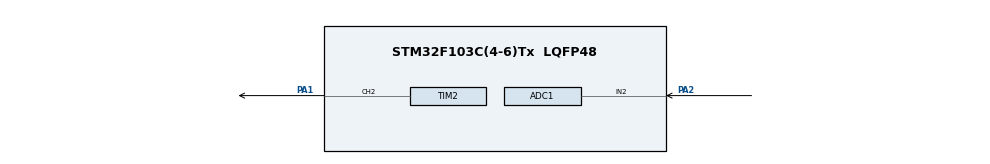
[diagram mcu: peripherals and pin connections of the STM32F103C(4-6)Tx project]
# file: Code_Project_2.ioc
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ADC1.Channel-1\#ChannelRegularConversion=ADC_CHANNEL_2
ADC1.ExternalTrigConv=ADC_SOFTWARE_START
ADC1.NbrOfConversion=1
ADC1.NbrOfConversionFlag=1
ADC1.Rank-1\#ChannelRegularConversion=1
ADC1.SamplingTime-1\#ChannelRegularConversion=ADC_SAMPLETIME_1CYCLE_5
ADC1.master=1
Mcu.Family=STM32F1
Mcu.Name=STM32F103C(4-6)Tx
Mcu.Package=LQFP48
NVIC.PriorityGroup=NVIC_PRIORITYGROUP_4
PA1.Signal=S_TIM2_CH2
PA13.Mode=Serial_Wire
PA13.Signal=SYS_JTMS-SWDIO
PA14.Mode=Serial_Wire
PA14.Signal=SYS_JTCK-SWCLK
PA2.Signal=ADCx_IN2
ProjectManager.HeapSize=0x200
ProjectManager.StackSize=0x400
ProjectManager.TargetToolchain=STM32CubeIDE
RCC.APB1Freq_Value=8000000
RCC.APB2Freq_Value=8000000
SH.ADCx_IN2.0=ADC1_IN2,IN2
SH.S_TIM2_CH2.0=TIM2_CH2,PWM Generation2 CH2
TIM2.Channel-PWM\ Generation2\ CH2=TIM_CHANNEL_2
TIM2.Period=99
TIM2.Prescaler=79
TIM2.Pulse-PWM\ Generation2\ CH2=10
VP_TIM2_VS_ClockSourceINT.Mode=Internal
board=custom

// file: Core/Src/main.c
/* USER CODE BEGIN Header */
/**
  ******************************************************************************
  * @file           : main.c
  * @brief          : Main program body
  ******************************************************************************
  * @attention
  *
  * <h2><center>&copy; Copyright (c) 2021 STMicroelectronics.
  * All rights reserved.</center></h2>
  *
  * This software component is licensed by ST under BSD 3-Clause license,
  * the "License"; You may not use this file except in compliance with the
  * License. You may obtain a copy of the License at:
  *                        opensource.org/licenses/BSD-3-Clause
  *
  ******************************************************************************
  */
/* USER CODE END Header */
#include "main.h"

ADC_HandleTypeDef hadc1;

TIM_HandleTypeDef htim2;

/* USER CODE BEGIN PV */

//variable for PID
float 	 alpha = 0, beta = 0, gamma = 0;
uint8_t  duty = 0, pre_duty = 0;

/* USER CODE END PV */

void SystemClock_Config(void);
static void MX_GPIO_Init(void);
static void MX_ADC1_Init(void);
static void MX_TIM2_Init(void);
/* USER CODE BEGIN PFP */
void TIM2_PWM_Set_Duty(uint8_t duty);
void TIM2_PWM_Set_Frequency(uint32_t frequency);
/* USER CODE END PFP */

int main(void)
{

  /* MCU Configuration--------------------------------------------------------*/

  /* Reset of all peripherals, Initializes the Flash interface and the Systick. */
  HAL_Init();

  /* USER CODE BEGIN Init */
  Lcd_Init();
  /* USER CODE END Init */

  /* Configure the system clock */
  SystemClock_Config();

  /* Initialize all configured peripherals */
  MX_GPIO_Init();
  MX_ADC1_Init();
  MX_TIM2_Init();
  /* USER CODE BEGIN 2 */
  Lcd_display(10, 1000);

  TIM2_PWM_Set_Duty(10);
  TIM2_PWM_Set_Frequency(2000);
  if( HAL_TIM_PWM_Start(&htim2, TIM_CHANNEL_2) != HAL_OK)
  {
	  Error_Handler();
  }
  /* USER CODE END 2 */

  /* Infinite loop */
  /* USER CODE BEGIN WHILE */
  uint8_t temperature;
  while (1)
  {

//	  while(duty <= 100)
//	  {
//		  TIM2_PWM_Set_Duty(duty);
//		  HAL_Delay(50);
//		  duty += 5;
//	  }
//	  duty = 0;

	HAL_ADC_Start(&hadc1);
	temperature = ((float)HAL_ADC_GetValue(&hadc1) / 4096) * 3.3 * 100;
	Lcd_display(temperature, 500);
	HAL_Delay(1000);
    /* USER CODE END WHILE */

  }
}

void SystemClock_Config(void)
{
  RCC_OscInitTypeDef RCC_OscInitStruct = {0};
  RCC_ClkInitTypeDef RCC_ClkInitStruct = {0};
  RCC_PeriphCLKInitTypeDef PeriphClkInit = {0};

  /** Initializes the RCC Oscillators according to the specified parameters
  * in the RCC_OscInitTypeDef structure.
  */
  RCC_OscInitStruct.OscillatorType = RCC_OSCILLATORTYPE_HSI;
  RCC_OscInitStruct.HSIState = RCC_HSI_ON;
  RCC_OscInitStruct.HSICalibrationValue = RCC_HSICALIBRATION_DEFAULT;
  RCC_OscInitStruct.PLL.PLLState = RCC_PLL_NONE;
  if (HAL_RCC_OscConfig(&RCC_OscInitStruct) != HAL_OK)
  {
    Error_Handler();
  }
  /** Initializes the CPU, AHB and APB buses clocks
  */
  RCC_ClkInitStruct.ClockType = RCC_CLOCKTYPE_HCLK|RCC_CLOCKTYPE_SYSCLK
                              |RCC_CLOCKTYPE_PCLK1|RCC_CLOCKTYPE_PCLK2;
  RCC_ClkInitStruct.SYSCLKSource = RCC_SYSCLKSOURCE_HSI;
  RCC_ClkInitStruct.AHBCLKDivider = RCC_SYSCLK_DIV1;
  RCC_ClkInitStruct.APB1CLKDivider = RCC_HCLK_DIV1;
  RCC_ClkInitStruct.APB2CLKDivider = RCC_HCLK_DIV1;

  if (HAL_RCC_ClockConfig(&RCC_ClkInitStruct, FLASH_LATENCY_0) != HAL_OK)
  {
    Error_Handler();
  }
  PeriphClkInit.PeriphClockSelection = RCC_PERIPHCLK_ADC;
  PeriphClkInit.AdcClockSelection = RCC_ADCPCLK2_DIV2;
  if (HAL_RCCEx_PeriphCLKConfig(&PeriphClkInit) != HAL_OK)
  {
    Error_Handler();
  }
}

static void MX_ADC1_Init(void)
{

  ADC_ChannelConfTypeDef sConfig = {0};

  /** Common config
  */
  hadc1.Instance = ADC1;
  hadc1.Init.ScanConvMode = ADC_SCAN_DISABLE;
  hadc1.Init.ContinuousConvMode = DISABLE;
  hadc1.Init.DiscontinuousConvMode = DISABLE;
  hadc1.Init.ExternalTrigConv = ADC_SOFTWARE_START;
  hadc1.Init.DataAlign = ADC_DATAALIGN_RIGHT;
  hadc1.Init.NbrOfConversion = 1;
  if (HAL_ADC_Init(&hadc1) != HAL_OK)
  {
    Error_Handler();
  }
  /** Configure Regular Channel
  */
  sConfig.Channel = ADC_CHANNEL_2;
  sConfig.Rank = ADC_REGULAR_RANK_1;
  sConfig.SamplingTime = ADC_SAMPLETIME_1CYCLE_5;
  if (HAL_ADC_ConfigChannel(&hadc1, &sConfig) != HAL_OK)
  {
    Error_Handler();
  }

}

static void MX_TIM2_Init(void)
{

  TIM_ClockConfigTypeDef sClockSourceConfig = {0};
  TIM_MasterConfigTypeDef sMasterConfig = {0};
  TIM_OC_InitTypeDef sConfigOC = {0};

  htim2.Instance = TIM2;
  htim2.Init.Prescaler = 79;
  htim2.Init.CounterMode = TIM_COUNTERMODE_UP;
  htim2.Init.Period = 99;
  htim2.Init.ClockDivision = TIM_CLOCKDIVISION_DIV1;
  htim2.Init.AutoReloadPreload = TIM_AUTORELOAD_PRELOAD_DISABLE;
  if (HAL_TIM_Base_Init(&htim2) != HAL_OK)
  {
    Error_Handler();
  }
  sClockSourceConfig.ClockSource = TIM_CLOCKSOURCE_INTERNAL;
  if (HAL_TIM_ConfigClockSource(&htim2, &sClockSourceConfig) != HAL_OK)
  {
    Error_Handler();
  }
  if (HAL_TIM_PWM_Init(&htim2) != HAL_OK)
  {
    Error_Handler();
  }
  sMasterConfig.MasterOutputTrigger = TIM_TRGO_RESET;
  sMasterConfig.MasterSlaveMode = TIM_MASTERSLAVEMODE_DISABLE;
  if (HAL_TIMEx_MasterConfigSynchronization(&htim2, &sMasterConfig) != HAL_OK)
  {
    Error_Handler();
  }
  sConfigOC.OCMode = TIM_OCMODE_PWM1;
  sConfigOC.Pulse = 10;
  sConfigOC.OCPolarity = TIM_OCPOLARITY_HIGH;
  sConfigOC.OCFastMode = TIM_OCFAST_DISABLE;
  if (HAL_TIM_PWM_ConfigChannel(&htim2, &sConfigOC, TIM_CHANNEL_2) != HAL_OK)
  {
    Error_Handler();
  }
  HAL_TIM_MspPostInit(&htim2);

}

static void MX_GPIO_Init(void)
{

  /* GPIO Ports Clock Enable */
  __HAL_RCC_GPIOA_CLK_ENABLE();

}

/* USER CODE BEGIN 4 */

/**
  * @brief GPIO Initialization Function
  * @param Duty(%) 0 -> 100. % High voltage
  * @retval None
  */
void TIM2_PWM_Set_Duty(uint8_t duty)
{
	uint16_t compare = (htim2.Init.Period + 1) * duty / 100;
	__HAL_TIM_SET_COMPARE(&htim2, TIM_CHANNEL_2, compare);
}

/**
  * @brief GPIO Initialization Function
  * @param frequency(Hz); 2 < f < 80000
  * @retval None
  */
void TIM2_PWM_Set_Frequency(uint32_t frequency)
{
	// Fixed Period = 99
	// frequency = f_timer / [(Period + 1) * (Psc + 1)]
	// -> Psc = f_timer / (100 * frequency) - 1;
	uint32_t f_timer = HAL_RCC_GetPCLK1Freq() * 1; 	 //1 is APB1 time multiplier value
	TIM2->PSC = f_timer / (100 * frequency) - 1;

}

/**
  * @brief Config PID
  * @param T: sampling cycle: recommend value = 0.01s
  * @retval None
  */
void PID_Config(uint8_t Kp, uint8_t Ki, uint8_t Kd, float T)
{
	alpha = 2*T*Kp + Ki*T*T + 2*Kd;
	beta = T*T*Ki - 4*Kd - 2*T*Kp;
	gamma = 2*Kd;

}

/**
  * @brief Config PID
  * @param
  * @retval None
  */
void PID(uint16_t setPoint_Speed, uint16_t actual_Speed)
{
	static uint16_t e0 = 0, e1 = 0, e2 = 0;
	e0 = setPoint_Speed - actual_Speed;
	duty = (alpha*e0 + beta*e1 + gamma*e2 + pre_duty) / (2*T);
	pre_duty = duty;
	e2 = e1;
	e1 = e0;
	TIM2_PWM_Set_Duty(duty);
}

/* USER CODE END 4 */

void Error_Handler(void)
{
  __disable_irq();
  while (1)
  {
  }
}

/************************ (C) COPYRIGHT STMicroelectronics *****END OF FILE****/
